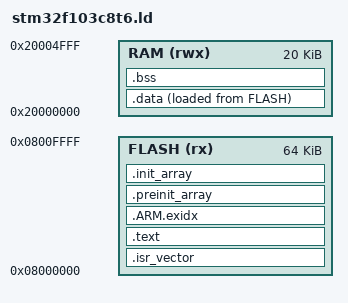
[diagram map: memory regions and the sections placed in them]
/* STM32F103C8T6 có Flash 64 KiB và SRAM 20 KiB. */
ENTRY(Reset_Handler)

MEMORY
{
    FLASH (rx)  : ORIGIN = 0x08000000, LENGTH = 64K
    RAM   (rwx) : ORIGIN = 0x20000000, LENGTH = 20K
}

_estack = ORIGIN(RAM) + LENGTH(RAM);
_min_stack_size = 0x400;

SECTIONS
{
    .isr_vector :
    {
        . = ALIGN(256);
        KEEP(*(.isr_vector))
    } > FLASH

    .text :
    {
        . = ALIGN(4);
        *(.text*)
        *(.rodata*)
        *(.ARM.extab*)
        . = ALIGN(4);
    } > FLASH

    .ARM.exidx :
    {
        __exidx_start = .;
        *(.ARM.exidx*)
        __exidx_end = .;
    } > FLASH

    .preinit_array :
    {
        . = ALIGN(4);
        __preinit_array_start = .;
        KEEP(*(.preinit_array*))
        __preinit_array_end = .;
    } > FLASH

    .init_array :
    {
        . = ALIGN(4);
        __init_array_start = .;
        KEEP(*(SORT_BY_INIT_PRIORITY(.init_array.*)))
        KEEP(*(.init_array))
        __init_array_end = .;
    } > FLASH

    _sidata = LOADADDR(.data);
    .data :
    {
        . = ALIGN(4);
        _sdata = .;
        *(.data*)
        . = ALIGN(4);
        _edata = .;
    } > RAM AT > FLASH

    .bss (NOLOAD) :
    {
        . = ALIGN(4);
        _sbss = .;
        *(.bss*)
        *(COMMON)
        . = ALIGN(4);
        _ebss = .;
    } > RAM

    /DISCARD/ : { *(.note.GNU-stack) *(.comment) }
}

ASSERT(_ebss <= _estack - _min_stack_size, "SRAM khong du cho stack 1 KiB")
